# IMM100A register map
Vendor: Infineon; File version: 0.8.0 (Reference Manual v0.8.0)
CPU: CM0 r0p0, little endian, no MPU, no FPU, 2 interrupt priority bits
Registers are 32-bit, read-write, reset 0x0 unless marked. A register's access mark holds for its fields unless they carry their own. Offsets are from the block's base; [hi:lo] are bit positions; {n}, {i} and the like mark numbered series; 'fields as' and 'values as' point back to an identical list; <NAME> marks a mode.

## SCU_POWER — System Control Unit
Base 0x40010200
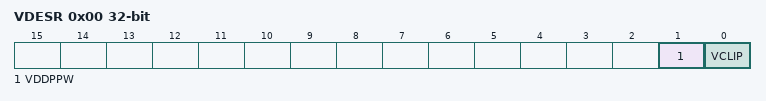
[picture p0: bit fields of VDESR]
0x00 VDESR ro — Voltage Detector Status Register
  [1] VDDPPW — VDDPPW Indication
    0=VDDP is above pre-warning threshold; 1=VDDP is below pre-warningthreshold
  [0] VCLIP — VCLIP Indication
    0=VCLIP is not active; 1=VCLIP is active

## SCU_RESET — System Control Unit
Base 0x40010400
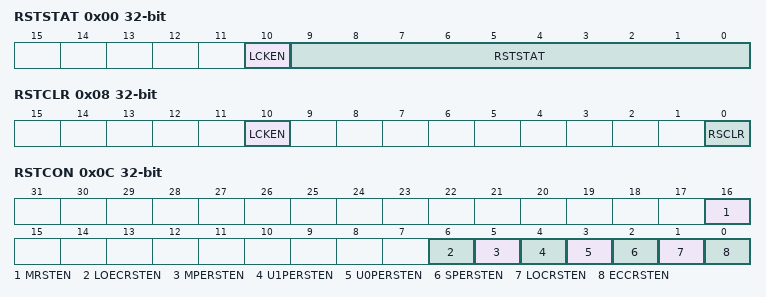
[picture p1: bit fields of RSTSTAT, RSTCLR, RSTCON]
0x00 RSTSTAT ro (reset mask 0xFFFFF000) — RCU Reset Status
  [10] LCKEN — Enable Lockup Status
    0=Reset by Lockup disabled; 1=Reset by Lockup enabled
  [9:0] RSTSTAT — Reset Status Information
0x04 RSTSET wo — RCU Reset Set Register
  [10] LCKEN — Enable Lockup Reset
    0=no effect; 1=Enable reset when Lockup gets asserted
0x08 RSTCLR wo — RCU Reset Clear Register
  [10] LCKEN — Enable Lockup Reset
    0=no effect; 1=Disable reset when Lockup gets asserted
  [0] RSCLR — Clear Reset Status
    0=no effect; 1=Clears field RSTSTAT.RSTSTAT
0x0C RSTCON access per field — RCU Reset Control Register
  [16] MRSTEN wo — Enable Master Reset
    0=No effect; 1=Triggered Master reset
  [6] LOECRSTEN rw — Enable Loss of External Clock Reset
    0=No reset when loss of external clock occur; 1=Reset when loss of external clock occur
  [5] MPERSTEN rw — Enable MultiCAN+SRAM Parity Error Reset
    0=No reset when MultiCAN+ memory parity error occur; 1=Reset when MultiCAN+ memory parity error occur
  [4] U1PERSTEN rw — Enable USIC01 SRAM Parity Error Reset
    0=No reset when USIC1 memory parity error occur; 1=Reset when USIC1 memory parity error occur
  [3] U0PERSTEN rw — Enable USIC0 SRAM Parity Error Reset
    0=No reset when USIC0 memory parity error occur; 1=Reset when USIC0 memory parity error occur
  [2] SPERSTEN rw — Enable 16kbytes SRAM Parity Error Reset
    0=No reset when SRAM parity error occur; 1=Reset when SRAM parity error occur
  [1] LOCRSTEN rw — Enable Loss of DCO1 Clock Reset
    0=No reset when loss of DCO1 clock occur; 1=Reset when loss of DCO1 clock occur
  [0] ECCRSTEN rw — Enable ECC Error Reset
    0=No reset when ECC double bit error occur; 1=Reset when ECC double bit error occur

## COMPARATOR — System Control Unit
Base 0x40010500
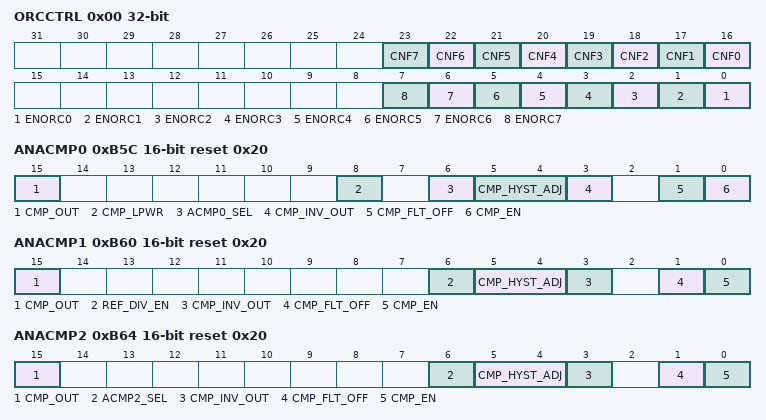
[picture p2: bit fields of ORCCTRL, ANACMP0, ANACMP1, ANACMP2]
0x00 ORCCTRL — Out Of Range Comparator Control Register
  [n+16] CNF{n} (n=0..7) — Out of Range Comparator Flag {n}
    0=Falling edge trigger out of range event register; 1=Rising edge trigger out of range event register
  [n] ENORC{n} (n=0..7) — Enable Out of Range Comparator {n}
    0=Out of range comparator disabled; 1=Out of range comparator enabled
0xB5C ANACMP0 16-bit access per field reset 0x20 — Analog Comparator 0 Control Register
  [15] CMP_OUT ro — Comparator output monitor bit
    0=state "Vminus > Vplus"; 1=state "Vminus < Vplus"
  [8] CMP_LPWR rw — Low Power Mode
    0=High Power Mode; 1=Low Power Mode
  [6] ACMP0_SEL rw — Connect ACMP0.INN to ACMP1.INP
    0=ACMP0.INN is not connected; 1=ACMP0.INN is connected to ACMP1.INP
  [5:4] CMP_HYST_ADJ rw — Comparator hysteresis adjust
    0=Comparator hysteresis is switched off; 1=Hysteresis_typ = 10mV; 2=Hysteresis_typ = 15mV; 3=Hysteresis_typ = 20mV
  [3] CMP_INV_OUT rw — Inverted Comparator output
    0=no inversion of comparator signal; 1=comparator signal is inverted
  [1] CMP_FLT_OFF rw — Disables comparator filter
    0=filter is active; 1=filter is switched off (to prevent a filter delay)
  [0] CMP_EN rw — Comparator enable
    0=Comparator is disabled; 1=Comparator is enabled
0xB60 ANACMP1 16-bit access per field reset 0x20 — Analog Comparator 1 Control Register
  [15] CMP_OUT ro — Comparator output monitor bit
    0=state "Vminus > Vplus"; 1=state "Vminus < Vplus"
  [6] REF_DIV_EN rw — Resistor Divider is enabled and Reference Voltage is applied to ACMP1
    0=no resistor is connected; 1=the divider resistor is enabled and the voltage is applied to ACMP1.INP
  [5:4] CMP_HYST_ADJ rw — Comparator hysteresis adjust
    values as ANACMP0.CMP_HYST_ADJ
  [3] CMP_INV_OUT rw — Inverted Comparator output
    values as ANACMP0.CMP_INV_OUT
  [1] CMP_FLT_OFF rw — Disables comparator filter
    values as ANACMP0.CMP_FLT_OFF
  [0] CMP_EN rw — Comparator enable
    0=Comparator is disabled; 1=Comparator is enabled
0xB64 ANACMP2 16-bit access per field reset 0x20 — Analog Comparator 2 Control Register
  [15] CMP_OUT ro — Comparator output monitor bit
    0=state "Vminus > Vplus"; 1=state "Vminus < Vplus"
  [6] ACMP2_SEL rw — Connect ACMP2.INP to ACMP1.INP
    0=ACMP2.INP is not connected; 1=ACMP2.INP is connected to ACMP1.INP
  [5:4] CMP_HYST_ADJ rw — Comparator hysteresis adjust
    values as ANACMP0.CMP_HYST_ADJ
  [3] CMP_INV_OUT rw — Inverted Comparator output
    values as ANACMP0.CMP_INV_OUT
  [1] CMP_FLT_OFF rw — Disables comparator filter
    values as ANACMP0.CMP_FLT_OFF
  [0] CMP_EN rw — Comparator enable
    0=Comparator is disabled; 1=Comparator is enabled
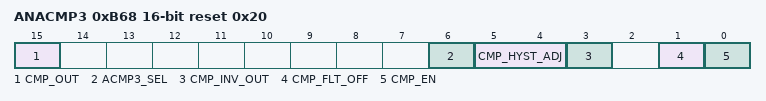
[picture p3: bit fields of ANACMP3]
0xB68 ANACMP3 16-bit access per field reset 0x20 — Analog Comparator 3 Control Register
  [15] CMP_OUT ro — Comparator output monitor bit
    0=state "Vminus > Vplus"; 1=state "Vminus < Vplus"
  [6] ACMP3_SEL rw — Connect ACMP3.INP to ACMP1.INP
    0=ACMP3.INP is not connected; 1=ACMP3.INP is connected to ACMP1.INP
  [5:4] CMP_HYST_ADJ rw — Comparator hysteresis adjust
    values as ANACMP0.CMP_HYST_ADJ
  [3] CMP_INV_OUT rw — Inverted Comparator output
    values as ANACMP0.CMP_INV_OUT
  [1] CMP_FLT_OFF rw — Disables comparator filter
    values as ANACMP0.CMP_FLT_OFF
  [0] CMP_EN rw — Comparator enable
    0=Comparator is disabled; 1=Comparator is enabled
